AUTOSAR XML (schema 00044)
package /E40_Platform_System_SystemPackage/Components
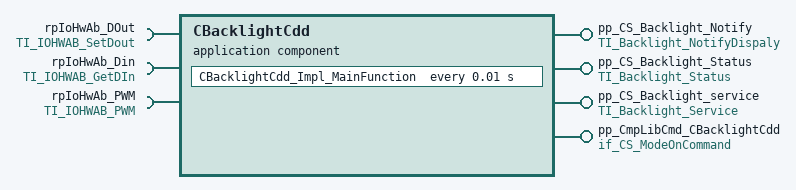
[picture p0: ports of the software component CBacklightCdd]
  application sw component type CBacklightCdd
    4 x provide port:
      pp_CS_Backlight_Notify: server-com-spec{operation=NotifyDisplayPowerState, queue-length=1}, provided-interface=TI_Backlight_NotifyDispaly
      pp_CS_Backlight_Status: server-com-spec{operation=GetStatus, queue-length=1}, provided-interface=TI_Backlight_Status
      pp_CS_Backlight_service: provided-interface=TI_Backlight_Service
        provided-com-specs:
          operation=GetBrightnessValue, queue-length=1
          operation=GetThermalValue, queue-length=1
          operation=SetBrightnessValue, queue-length=1
      pp_CmpLibCmd_CBacklightCdd: server-com-spec{operation=Impl_OnCommand, queue-length=1}, provided-interface=if_CS_ModeOnCommand
    require port rpIoHwAb_DOut: required-com-specs=[SetOutputGroup, SetOutputPin], required-interface=TI_IOHWAB_SetDout
    require port rpIoHwAb_Din: required-com-specs=[GetAsyncRawInput, GetInputGroup, GetProcessedInput, GetSyncRawInput], required-interface=TI_IOHWAB_GetDIn
    require port rpIoHwAb_PWM: required-com-specs=[PwmSetDuty, PwmSetDutyAndPeriod, PwmSetIdeal], required-interface=TI_IOHWAB_PWM
    behavior IB_CBacklightCdd
      operation invoked event OIE_pp_CS_Backlight_service_CBacklightCdd_GetBrightnessValueTrigByGetBrightnessValue: start-on-event=CBacklightCdd_GetBrightnessValue, operation=pp_CS_Backlight_service.GetBrightnessValue
      operation invoked event OIE_pp_CS_Backlight_Status_CBacklightCdd_GetStatusTrigByGetStatus: start-on-event=CBacklightCdd_GetStatus, operation=pp_CS_Backlight_Status.GetStatus
      operation invoked event OIE_pp_CS_Backlight_service_CBacklightCdd_GetThermalValueTrigByGetThermalValue: start-on-event=CBacklightCdd_GetThermalValue, operation=pp_CS_Backlight_service.GetThermalValue
      timing event TECBacklightCdd_Impl_MainFunction: start-on-event=CBacklightCdd_Impl_MainFunction, period=0.01
      operation invoked event OIE_pp_CmpLibCmd_CBacklightCdd_CBacklightCdd_Impl_OnCommandTrigByImpl_OnCommand: start-on-event=CBacklightCdd_Impl_OnCommand, operation=pp_CmpLibCmd_CBacklightCdd.Impl_OnCommand
      operation invoked event OIE_pp_CS_Backlight_Notify_CBacklightCdd_NotifyDisplayPowerStateTrigByNotifyDisplayPowerState: start-on-event=CBacklightCdd_NotifyDisplayPowerState, operation=pp_CS_Backlight_Notify.NotifyDisplayPowerState
      operation invoked event OIE_pp_CS_Backlight_service_CBacklightCdd_SetBrightnessValueTrigBySetBrightnessValue: start-on-event=CBacklightCdd_SetBrightnessValue, operation=pp_CS_Backlight_service.SetBrightnessValue
      port-api-options:
        enable-take-address=false, indirect-api=false, port=pp_CS_Backlight_Notify
        enable-take-address=false, indirect-api=false, port=pp_CS_Backlight_Status
        enable-take-address=false, indirect-api=false, port=pp_CS_Backlight_service
        enable-take-address=false, indirect-api=false, port=pp_CmpLibCmd_CBacklightCdd
        enable-take-address=false, indirect-api=false, port=rpIoHwAb_DOut
        enable-take-address=false, indirect-api=false, port=rpIoHwAb_Din
        enable-take-address=false, indirect-api=false, port=rpIoHwAb_PWM
      7 x runnable, all with can-be-invoked-concurrently=true:
        CBacklightCdd_GetBrightnessValue
          9 x sync call:
            OA_rpIoHwAb_DOut_SetOutputGroup: operation=rpIoHwAb_DOut.SetOutputGroup
            OA_rpIoHwAb_DOut_SetOutputPin: operation=rpIoHwAb_DOut.SetOutputPin
            OA_rpIoHwAb_Din_GetAsyncRawInput: operation=rpIoHwAb_Din.GetAsyncRawInput
            OA_rpIoHwAb_Din_GetProcessedInput: operation=rpIoHwAb_Din.GetProcessedInput
            OA_rpIoHwAb_Din_GetSyncRawInput: operation=rpIoHwAb_Din.GetSyncRawInput
            OA_rpIoHwAb_Din_GetInputGroup: operation=rpIoHwAb_Din.GetInputGroup
            OA_rpIoHwAb_PWM_PwmSetDuty: operation=rpIoHwAb_PWM.PwmSetDuty
            OA_rpIoHwAb_PWM_PwmSetDutyAndPeriod: operation=rpIoHwAb_PWM.PwmSetDutyAndPeriod
            OA_rpIoHwAb_PWM_PwmSetIdeal: operation=rpIoHwAb_PWM.PwmSetIdeal
        CBacklightCdd_GetStatus
          9 x sync call:
            OA_rpIoHwAb_DOut_SetOutputGroup: operation=rpIoHwAb_DOut.SetOutputGroup
            OA_rpIoHwAb_DOut_SetOutputPin: operation=rpIoHwAb_DOut.SetOutputPin
            OA_rpIoHwAb_Din_GetAsyncRawInput: operation=rpIoHwAb_Din.GetAsyncRawInput
            OA_rpIoHwAb_Din_GetProcessedInput: operation=rpIoHwAb_Din.GetProcessedInput
            OA_rpIoHwAb_Din_GetSyncRawInput: operation=rpIoHwAb_Din.GetSyncRawInput
            OA_rpIoHwAb_Din_GetInputGroup: operation=rpIoHwAb_Din.GetInputGroup
            OA_rpIoHwAb_PWM_PwmSetDuty: operation=rpIoHwAb_PWM.PwmSetDuty
            OA_rpIoHwAb_PWM_PwmSetDutyAndPeriod: operation=rpIoHwAb_PWM.PwmSetDutyAndPeriod
            OA_rpIoHwAb_PWM_PwmSetIdeal: operation=rpIoHwAb_PWM.PwmSetIdeal
        CBacklightCdd_GetThermalValue
          9 x sync call:
            OA_rpIoHwAb_DOut_SetOutputGroup: operation=rpIoHwAb_DOut.SetOutputGroup
            OA_rpIoHwAb_DOut_SetOutputPin: operation=rpIoHwAb_DOut.SetOutputPin
            OA_rpIoHwAb_Din_GetAsyncRawInput: operation=rpIoHwAb_Din.GetAsyncRawInput
            OA_rpIoHwAb_Din_GetProcessedInput: operation=rpIoHwAb_Din.GetProcessedInput
            OA_rpIoHwAb_Din_GetSyncRawInput: operation=rpIoHwAb_Din.GetSyncRawInput
            OA_rpIoHwAb_Din_GetInputGroup: operation=rpIoHwAb_Din.GetInputGroup
            OA_rpIoHwAb_PWM_PwmSetDuty: operation=rpIoHwAb_PWM.PwmSetDuty
            OA_rpIoHwAb_PWM_PwmSetDutyAndPeriod: operation=rpIoHwAb_PWM.PwmSetDutyAndPeriod
            OA_rpIoHwAb_PWM_PwmSetIdeal: operation=rpIoHwAb_PWM.PwmSetIdeal
        CBacklightCdd_Impl_MainFunction
          9 x sync call:
            OA_rpIoHwAb_DOut_SetOutputGroup: operation=rpIoHwAb_DOut.SetOutputGroup
            OA_rpIoHwAb_DOut_SetOutputPin: operation=rpIoHwAb_DOut.SetOutputPin
            OA_rpIoHwAb_Din_GetAsyncRawInput: operation=rpIoHwAb_Din.GetAsyncRawInput
            OA_rpIoHwAb_Din_GetProcessedInput: operation=rpIoHwAb_Din.GetProcessedInput
            OA_rpIoHwAb_Din_GetSyncRawInput: operation=rpIoHwAb_Din.GetSyncRawInput
            OA_rpIoHwAb_Din_GetInputGroup: operation=rpIoHwAb_Din.GetInputGroup
            OA_rpIoHwAb_PWM_PwmSetDuty: operation=rpIoHwAb_PWM.PwmSetDuty
            OA_rpIoHwAb_PWM_PwmSetDutyAndPeriod: operation=rpIoHwAb_PWM.PwmSetDutyAndPeriod
            OA_rpIoHwAb_PWM_PwmSetIdeal: operation=rpIoHwAb_PWM.PwmSetIdeal
        CBacklightCdd_Impl_OnCommand
          9 x sync call:
            OA_rpIoHwAb_DOut_SetOutputGroup: operation=rpIoHwAb_DOut.SetOutputGroup
            OA_rpIoHwAb_DOut_SetOutputPin: operation=rpIoHwAb_DOut.SetOutputPin
            OA_rpIoHwAb_Din_GetAsyncRawInput: operation=rpIoHwAb_Din.GetAsyncRawInput
            OA_rpIoHwAb_Din_GetProcessedInput: operation=rpIoHwAb_Din.GetProcessedInput
            OA_rpIoHwAb_Din_GetSyncRawInput: operation=rpIoHwAb_Din.GetSyncRawInput
            OA_rpIoHwAb_Din_GetInputGroup: operation=rpIoHwAb_Din.GetInputGroup
            OA_rpIoHwAb_PWM_PwmSetDuty: operation=rpIoHwAb_PWM.PwmSetDuty
            OA_rpIoHwAb_PWM_PwmSetDutyAndPeriod: operation=rpIoHwAb_PWM.PwmSetDutyAndPeriod
            OA_rpIoHwAb_PWM_PwmSetIdeal: operation=rpIoHwAb_PWM.PwmSetIdeal
        CBacklightCdd_NotifyDisplayPowerState
          9 x sync call:
            OA_rpIoHwAb_DOut_SetOutputGroup: operation=rpIoHwAb_DOut.SetOutputGroup
            OA_rpIoHwAb_DOut_SetOutputPin: operation=rpIoHwAb_DOut.SetOutputPin
            OA_rpIoHwAb_Din_GetAsyncRawInput: operation=rpIoHwAb_Din.GetAsyncRawInput
            OA_rpIoHwAb_Din_GetProcessedInput: operation=rpIoHwAb_Din.GetProcessedInput
            OA_rpIoHwAb_Din_GetSyncRawInput: operation=rpIoHwAb_Din.GetSyncRawInput
            OA_rpIoHwAb_Din_GetInputGroup: operation=rpIoHwAb_Din.GetInputGroup
            OA_rpIoHwAb_PWM_PwmSetDuty: operation=rpIoHwAb_PWM.PwmSetDuty
            OA_rpIoHwAb_PWM_PwmSetDutyAndPeriod: operation=rpIoHwAb_PWM.PwmSetDutyAndPeriod
            OA_rpIoHwAb_PWM_PwmSetIdeal: operation=rpIoHwAb_PWM.PwmSetIdeal
        CBacklightCdd_SetBrightnessValue
          9 x sync call:
            OA_rpIoHwAb_DOut_SetOutputGroup: operation=rpIoHwAb_DOut.SetOutputGroup
            OA_rpIoHwAb_DOut_SetOutputPin: operation=rpIoHwAb_DOut.SetOutputPin
            OA_rpIoHwAb_Din_GetAsyncRawInput: operation=rpIoHwAb_Din.GetAsyncRawInput
            OA_rpIoHwAb_Din_GetProcessedInput: operation=rpIoHwAb_Din.GetProcessedInput
            OA_rpIoHwAb_Din_GetSyncRawInput: operation=rpIoHwAb_Din.GetSyncRawInput
            OA_rpIoHwAb_Din_GetInputGroup: operation=rpIoHwAb_Din.GetInputGroup
            OA_rpIoHwAb_PWM_PwmSetDuty: operation=rpIoHwAb_PWM.PwmSetDuty
            OA_rpIoHwAb_PWM_PwmSetDutyAndPeriod: operation=rpIoHwAb_PWM.PwmSetDutyAndPeriod
            OA_rpIoHwAb_PWM_PwmSetIdeal: operation=rpIoHwAb_PWM.PwmSetIdeal
  swc implementation IMPL_CBacklightCdd: behavior=IB_CBacklightCdd
